# ipe5_target_db register map
Vendor: Texas Instruments
Peripheral module from a debugger description file (folder iva2_arp32).
Address unit: 16 bits
Registers are 32-bit, access per field, reset 0x0 unless marked. A register's access mark holds for its fields unless they carry their own. Offsets are as the file gives them; lines under a group give offsets from that group; [hi:lo] are bit positions; {n}, {i} and the like mark numbered series; 'fields as' and 'values as' point back to an identical list; <NAME> marks a mode.

## DSS (part 1 of 2) — ipxact12_to_ccs_generated
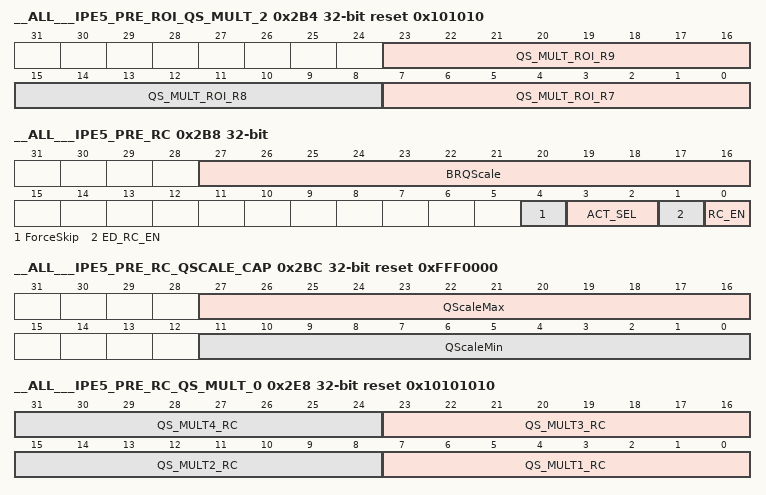
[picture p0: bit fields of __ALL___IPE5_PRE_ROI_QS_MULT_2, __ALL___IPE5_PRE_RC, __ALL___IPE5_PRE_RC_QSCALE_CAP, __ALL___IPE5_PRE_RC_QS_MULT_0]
0x2B4 __ALL___IPE5_PRE_ROI_QS_MULT_2 reset 0x101010 — Multiplication Factors to modify the row level Qscale with. The factors are in Q4.4 format. modifiedQscale = (baseRowQscale * QS_MULT_ROI_Rx) >> 4.
  [23:16] QS_MULT_ROI_R9 rw — 8-bit Qscale multiplication factor.
  [15:8] QS_MULT_ROI_R8 rw — 8-bit Qscale multiplication factor.
  [7:0] QS_MULT_ROI_R7 rw — 8-bit Qscale multiplication factor.
0x2B8 __ALL___IPE5_PRE_RC — IPE5 Rate Control register.
  [27:16] BRQScale rw — Base ROW level Qscale value. Expressed in Q4 format. To be programmed by ICONT at row level.
  [4] ForceSkip rw — ForceSkip information to be updated by ICONT at row level along with BRQScale. This information is passed onto IME and consumed by IPE5.
  [3:2] ACT_SEL rw — Activity select option. 00 : Choose 16X16 activity. 01 : Choose 8X8 activity. 10 : Choose 4X4 activity. 11 : Reserved. If set, by default will use 4X4 activity.
  [1] ED_RC_EN rw — Edge Detection result to be used for Rate control. 0: Text Detection result is not used. 1: Text detection result will modify Qscale for Rate Control.
  [0] RC_EN rw — Enable bit for IPE5 rate control. 0 : Rate control is disabled. 1 : Rate control is enabled.
0x2BC __ALL___IPE5_PRE_RC_QSCALE_CAP reset 0xFFF0000 — Maximum and Minimum values of QScale to be used. The RC modified QScale will be clipped in this range.
  [27:16] QScaleMax rw — MaximumQScale for the current picture.
  [11:0] QScaleMin rw — Minimum QScale for the current picture.
{0x2BC+4i} __ALL___IPE5_PRE_RC_TH{i}_H (i=1..5) — Previous picture activity threshold {i}. 19 bits for 16X16 in case of 8bpp. 17 bits for 8X8 in case of 8bpp. 15 bits for 4X4 in case of 8bpp.
  [18:0] ACT_TH{i}_H rw — Previous frame activity based Threshold.
{0x2BC+4i} __ALL___IPE5_PRE_RC_TH{i}_L (i=6..10) — Previous picture activity threshold {i}. 19 bits for 16X16 in case of 8bpp. 17 bits for 8X8 in case of 8bpp. 15 bits for 4X4 in case of 8bpp.
  [18:0] ACT_TH{i}_L rw — Previous frame activity based Threshold.
0x2E8 __ALL___IPE5_PRE_RC_QS_MULT_0 rw reset 0x10101010 — Multiplication Factors to modify the row level Qscale with. The factors are in Q4.4 format. modifiedQscale = (baseRowQscale * QS_MULTx_RC ) >> 4.
  [8n-1:8n-8] QS_MULT{n}_RC (n=1..4) — 8-bit Qscale multiplication factor.
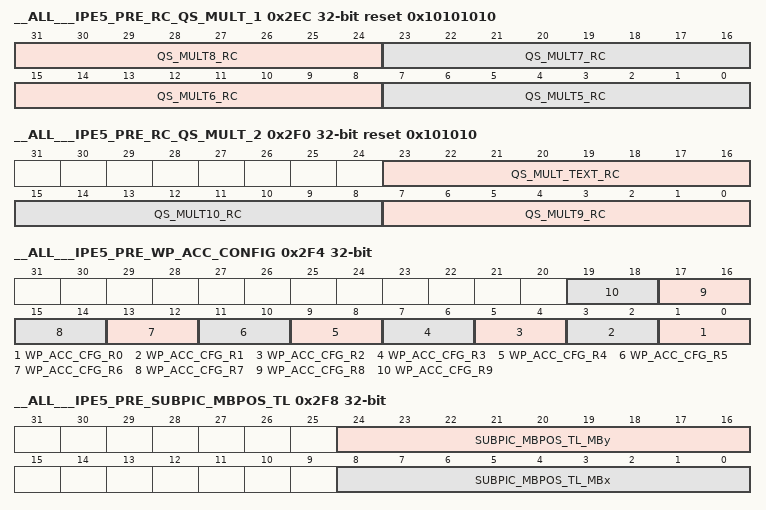
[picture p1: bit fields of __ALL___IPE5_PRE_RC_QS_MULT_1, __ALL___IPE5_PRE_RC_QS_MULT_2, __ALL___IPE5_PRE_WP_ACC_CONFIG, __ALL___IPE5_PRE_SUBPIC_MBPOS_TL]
0x2EC __ALL___IPE5_PRE_RC_QS_MULT_1 rw reset 0x10101010 — Multiplication Factors to modify the row level Qscale with. The factors are in Q4.4 format. modifiedQscale = (baseRowQscale * QS_MULTx_RC ) >> 4.
  [31:24] QS_MULT8_RC — 8-bit Multipliation factor for QScale modulation in text regions.
  [23:16] QS_MULT7_RC — 8-bit Qscale multiplication factor.
  [15:8] QS_MULT6_RC — 8-bit Qscale multiplication factor.
  [7:0] QS_MULT5_RC — 8-bit Qscale multiplication factor.
0x2F0 __ALL___IPE5_PRE_RC_QS_MULT_2 reset 0x101010 — Multiplication Factors to modify the row level Qscale with. The factors are in Q4.4 format. modifiedQscale = (baseRowQscale * QS_MULTx _RC) >> 4.
  [23:16] QS_MULT_TEXT_RC rw — 8-bit Qscale multiplication factor.
  [15:8] QS_MULT10_RC rw — 8-bit Qscale multiplication factor.
  [7:0] QS_MULT9_RC rw — 8-bit Qscale multiplication factor.
0x2F4 __ALL___IPE5_PRE_WP_ACC_CONFIG — Weighted Prediction accumulator feature control register.
  [2n+1:2n] WP_ACC_CFG_R{n} rw (n=0..9) — Region{n} accumulation for sum and sum_sqr for even and odd lines control. 0=> sum/sum_sqr is both odd and even lines. 1=> sum/sum_sqr is for odd lines only. 2,3=> sum/sum_sqr is for even lines only.
0x2F8 __ALL___IPE5_PRE_SUBPIC_MBPOS_TL — Top and Left position of MB for a sub-picture where pre-encode pass will operate on.
  [24:16] SUBPIC_MBPOS_TL_MBy rw — MBy value.
  [8:0] SUBPIC_MBPOS_TL_MBx rw — MBx value.
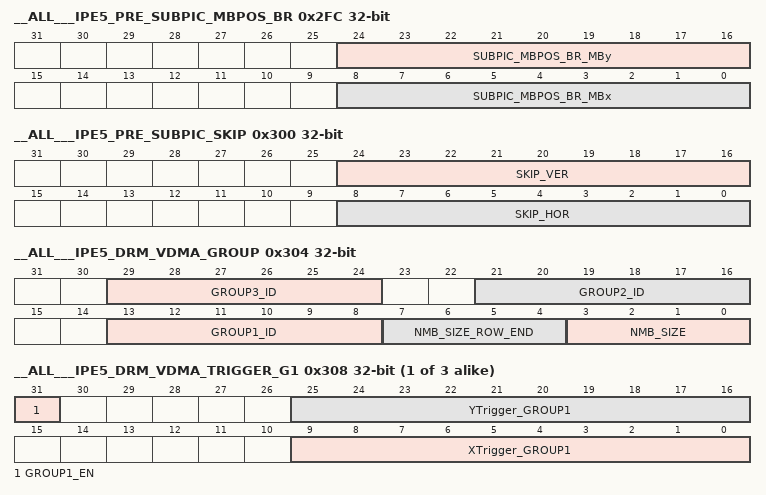
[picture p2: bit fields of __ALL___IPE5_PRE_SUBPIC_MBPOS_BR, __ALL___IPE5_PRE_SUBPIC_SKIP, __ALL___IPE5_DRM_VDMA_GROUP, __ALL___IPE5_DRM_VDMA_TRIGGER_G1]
0x2FC __ALL___IPE5_PRE_SUBPIC_MBPOS_BR — Right and Bottom position of MB for a sub-picture where pre-encode pass will operate on.
  [24:16] SUBPIC_MBPOS_BR_MBy rw — MBy value.
  [8:0] SUBPIC_MBPOS_BR_MBx rw — MBx value.
0x300 __ALL___IPE5_PRE_SUBPIC_SKIP — The register has information on N MB's to pick per VDMA access. Register also has details on horizontal and vertical skip in the sub-picture. Used only for pre-encode pass.
  [24:16] SKIP_VER rw — Vertical skip value in sub-picture. For 8K rows, the maximum value can be expressed in 9-bits.
  [8:0] SKIP_HOR rw — Horizontal skip value in sub-picture. For a 8K row, the maximum value can be expressed in 9-bits.
0x304 __ALL___IPE5_DRM_VDMA_GROUP — VDMA Trigger Interface control MMR.
  [29:24] GROUP3_ID rw — Group3 ID. Only valid in full-encode pass interlaced input and used for last row of frame when MB padding is needed. If MB-padding is not needed this group is not needed.
  [21:16] GROUP2_ID rw — Group2 ID. Only valid in full-encode pass and used for last row of frame when MB padding is needed. If MB-padding is not needed this group is not needed.
  [13:8] GROUP1_ID rw — Group1 ID. This is a 6-bit value. Only group 1 is valid for pre-encode pass.
  [7:4] NMB_SIZE_ROW_END rw — Value of number of MB fetch at the row end. This value is always less and N. The supported values are 0 to 15. 0000 : 0 (Default, indicates M is not used) 0001 : M=1 0010 : M=2 0011 : M=3 0100 : M=4 ... 1111 : M=15
  [3:0] NMB_SIZE rw — Number of MB's to fetch for original pixels for non end of row. N can be end of row fetch also, in case width is a multiple of N. Supported values of N are 1 to 16. 0000 : N = 1 0001 : N = 2 0010 : N = 3 0011 : N = 4 ... 1111 : N = 16
{0x304+4i} __ALL___IPE5_DRM_VDMA_TRIGGER_G{i} (i=1..3) — Group{i} trigger control. IPE5 DRM VDMA MMR to indicate the number of triggers needed for the Group{i} MB's.
  [31] GROUP{i}_EN rw — Enable bit for GROUP{i}. 1=> GROUP{i} enabled. 0=> GROUP{i} disabled.
  [25:16] YTrigger_GROUP{i} rw — Indicates the number of rows (Y triggers) in group{i}.
  [9:0] XTrigger_GROUP{i} rw — Indicates the number of triggers in X direction needed for Group {i}.
0x400 __ALL___PID ro reset 0x4C070300 — IPE5 Peripheral ID Register.
  [31:0] PID — Peripheral ID value. This is still not the final value.
0x404 __ALL___SYSCONFIG — Control Register for IPGenericSYSCONFIG.
  [0] SOFTRESET rw — Software reset Read0: Reset done, no pending action Read1: Reset (software or other) on going Write0: No action Write1: Initiate software reset
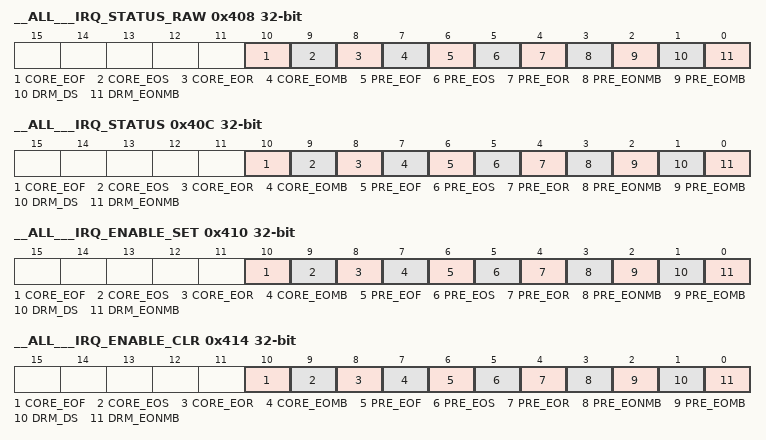
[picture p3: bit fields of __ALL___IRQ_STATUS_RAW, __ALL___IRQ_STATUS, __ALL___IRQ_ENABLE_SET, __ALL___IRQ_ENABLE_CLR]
0x408 __ALL___IRQ_STATUS_RAW — RAW interrupt status for IPE5. Raw status is set even if event is not enabled. Write 1 to set the (raw) status, mostly for debug. The following is the behavior for read/write into each of the individual fields : Write 0: No action Write 1: Set event (for debug) Read 0: No event pending Read 1: Event pending
  [10] CORE_EOF rw — CORE End of Frame Status
  [9] CORE_EOS rw — CORE End of Slice Status
  [8] CORE_EOR rw — CORE End of Row Status
  [7] CORE_EOMB rw — CORE End of MB Status
  [6] PRE_EOF rw — PRE End of Frame Status
  [5] PRE_EOS rw — PRE End of Slice Status
  [4] PRE_EOR rw — PRE End of Row Status
  [3] PRE_EONMB rw — PRE End of N MB status
  [2] PRE_EOMB rw — PRE End of MB Status
  [1] DRM_DS rw — DRM Data Sync Status.
  [0] DRM_EONMB rw — DRM End of N MacroBlock fetch Status.
0x40C __ALL___IRQ_STATUS — Status of enabled sources for interrupt IPE5. The individual status bits are not set, unless the source is enabled (by setting corresponding bit in IRQ_ENABLE_SET register) Write "1" to specific bit in this register to clear the status after interrupt has been serviced. Note : Writing "1" clears the "raw" status as well Note : Writing "1" generates internal EOI. The interrupt line is pulsed again, if any of the interrupt sources are still active (any of the status bits are "1") after the write of "1". The following is the behavior for read/write into each of the individual fields : Write 0: No action Write 1: Clear (raw) event - clears the corresponding bit in this register as well as the "raw" status bit in the IRQ_STATUS_RAW register Read 0: No enabled event pending Read 1: Event pending
  [10] CORE_EOF rw — CORE End of Frame status
  [9] CORE_EOS rw — CORE End of Slice status
  [8] CORE_EOR rw — CORE End of Row status
  [7] CORE_EOMB rw — CORE End of MB status
  [6] PRE_EOF rw — PRE End of Frame status
  [5] PRE_EOS rw — PRE End of Slice status
  [4] PRE_EOR rw — PRE End of Row status
  [3] PRE_EONMB rw — PRE End of N MB status
  [2] PRE_EOMB rw — PRE End of MB status
  [1] DRM_DS rw — DRM Data Sync Interrupt Status.
  [0] DRM_EONMB rw — DRM End of N MacroBlock fetch Status.
0x410 __ALL___IRQ_ENABLE_SET — Interrupt enable for each of the sources for interrupt IPE5. Writing "1" to specific field in this register enables the corresponding source for interrupt generatation The read value reflects whether the corresponding source is enabled/disabled for interrupt generation The following is the behavior for read/write into each of the individual fields : Write 0: No action Write 1: Enable interrupt Read 0: Interrupt disabled (masked) Read 1: Interrupt enabled
  [10] CORE_EOF rw — CORE End of Frame interrupt enable
  [9] CORE_EOS rw — CORE End of Slice interrupt enable
  [8] CORE_EOR rw — CORE End of Row interrupt enable
  [7] CORE_EOMB rw — CORE End of MB interrupt enable
  [6] PRE_EOF rw — PRE End of Frame interrupt enable
  [5] PRE_EOS rw — PRE End of Slice interrupt enable
  [4] PRE_EOR rw — PRE End of Row interrupt enable
  [3] PRE_EONMB rw — PRE End of N MB Interrupt Enable
  [2] PRE_EOMB rw — PRE End of MB interrupt enable
  [1] DRM_DS rw — DRM Data Sync Interrupt enable.
  [0] DRM_EONMB rw — DRM End of N MacroBlock Interrupt Enable.
0x414 __ALL___IRQ_ENABLE_CLR — Interrupt disable for each of the sources for interrupt IPE5. Writing "1" to specific field in this register disables the corresponding source for interrupt generatation The read value reflects whether the corresponding source is enabled/disabled for interrupt generation The following is the behavior for read/write into each of the individual fields : Write 0: No action Write 1: Disable interrupt Read 0: Interrupt disabled (masked) Read 1: Interrupt enabled
  [10] CORE_EOF rw — PRE End of Frame interrupt disable
  [9] CORE_EOS rw — PRE End of Slice interrupt disable
  [8] CORE_EOR rw — PRE End of Row interrupt disable
  [7] CORE_EOMB rw — CORE End of MB interrupt disable
  [6] PRE_EOF rw — PRE End of Frame interrupt disable
  [5] PRE_EOS rw — PRE End of Slice interrupt disable
  [4] PRE_EOR rw — PRE End of Row interrupt disable
  [3] PRE_EONMB rw — PRE End of N MB Interrupt Disable.
  [2] PRE_EOMB rw — PRE End of MB interrupt disable
  [1] DRM_DS rw — DRM Data Sync Interrupt disable.
  [0] DRM_EONMB rw — DRM End of N MacroBlock Interrupt disable.
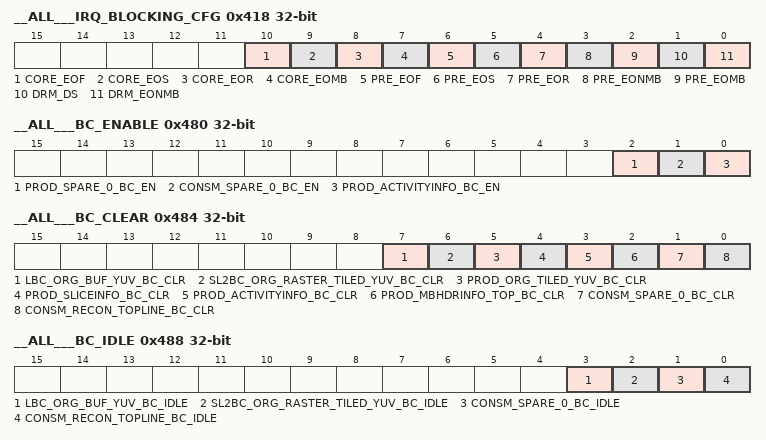
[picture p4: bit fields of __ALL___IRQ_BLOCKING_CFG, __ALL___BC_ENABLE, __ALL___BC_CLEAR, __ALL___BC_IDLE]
0x418 __ALL___IRQ_BLOCKING_CFG — Interrupt blocking configuration for interrupt IPE5. If a bit in this register is set to "1", the IPE5-DRM thread halts after it generates an interrupt for the corresponding interrupt source, and waits for interrupt acknowledgement for that interrupt line before continuing execution. If a bit in this register is set to "0", the IPE5-DRM does not halt after it generates an interrupt for the corresponding interrupt source The configuration in this register only apply to enabled interrupt sources.
  [10] CORE_EOF rw — CORE End of Frame Interrupt blocking configuration.
  [9] CORE_EOS rw — CORE End of Slice Interrupt blocking configuration.
  [8] CORE_EOR rw — CORE End of Row Interrupt blocking configuration.
  [7] CORE_EOMB rw — CORE End of MB Interrupt blocking configuration.
  [6] PRE_EOF rw — PRE End of Frame Interrupt blocking configuration.
  [5] PRE_EOS rw — PRE End of Slice Interrupt blocking configuration.
  [4] PRE_EOR rw — PRE End of Row Interrupt blocking configuration.
  [3] PRE_EONMB rw — PRE End of N MB Interrupt blocking Configuration
  [2] PRE_EOMB rw — PRE End of MB Interrupt blocking configuration.
  [1] DRM_DS rw — DRM Data Sync Interrupt blocking configuration.
  [0] DRM_EONMB rw — DRM End of N MacroBlock Interrupt blocking configuration.
0x480 __ALL___BC_ENABLE — BC_ENABLE Bits for specific BC's instantiated in IPE5. If this register is 0, the corresponding BC's ready is not looked for thread to proceed its execution.
  [2] PROD_SPARE_0_BC_EN rw — BC_ENABLE bit for PROD_SPARE_0 SL2BC. If set to '0', then BC availability is not checked for MB execution.
  [1] CONSM_SPARE_0_BC_EN rw — BC_ENABLE bit for CONSM_SPARE_0 SL2BC. If set to '0', then BC availability is not checked for MB execution.
  [0] PROD_ACTIVITYINFO_BC_EN rw — BC_ENABLE bit for ACTIVITYNIFO SL2BC. If set to '0', then activity info BC availability is not checked for MB execution and activity-info is not written into SL2.
0x484 __ALL___BC_CLEAR — BC_CLEAR Bits for all the BC's instantiated in IPE5. The bits set to '1' are auto-cleared in 1 cycle. So, the read will always yield '0'.
  [7] LBC_ORG_BUF_YUV_BC_CLR rw — BC_CLEAR bit for LBC_ORG_BUF LBC.
  [6] SL2BC_ORG_RASTER_TILED_YUV_BC_CLR rw — BC_CLEAR bit for SL2BC_ORG_RASTER_TILED_YUV SL2BC.
  [5] PROD_ORG_TILED_YUV_BC_CLR rw — BC_CLEAR bit for PROD_ORG_TILED_YUV SL2BC.
  [4] PROD_SLICEINFO_BC_CLR rw — BC_CLEAR bit for PROD_SLICEINFO SL2BC.
  [3] PROD_ACTIVITYINFO_BC_CLR rw — BC_CLEAR bit for PROD_ACTIVITYNIFO SL2BC.
  [2] PROD_MBHDRINFO_TOP_BC_CLR rw — BC_CLEAR bit for PROD_MBHDRINFO_TOP SL2BC.
  [1] CONSM_SPARE_0_BC_CLR rw — BC_CLEAR bit for CONSM_SPARE_0 SL2BC.
  [0] CONSM_RECON_TOPLINE_BC_CLR rw — BC_CLEAR bit for CONSM_RECON_TOPLINE SL2BC.
0x488 __ALL___BC_IDLE — BC_IDLE Bits for all the BC's instantiated in IPE5. The bits set to '1' are auto-cleared in 1 cycle. So, the read will always yield '0'.
  [3] LBC_ORG_BUF_YUV_BC_IDLE rw — BC_IDLE bit for LBC_ORG_BUF LBC.
  [2] SL2BC_ORG_RASTER_TILED_YUV_BC_IDLE rw — BC_IDLE bit for SL2BC_ORG_RASTER_TILED_YUV SL2BC.
  [1] CONSM_SPARE_0_BC_IDLE rw — BC_IDLE bit for CONSM_SPARE_0 SL2BC.
  [0] CONSM_RECON_TOPLINE_BC_IDLE rw — BC_IDLE bit for CONSM_RECON_TOPLINE SL2BC.
0x48C __ALL___START_OF_FRAME — Indicates that the start of a new frame to the IPE5. Self clearing bit. This will be used for all use cases. Write[0] : No impact Write[1] : Indicates start of frame for IPE5. Read[0] : Operation is not on SOF Read[1] : Operation is on SOF.
  [0] START_OF_FRAME rw — 1=> Indicates start of frame to IPE5. This has to be set by ICONT. 0=> Indicates that current operation is not on start of frame.
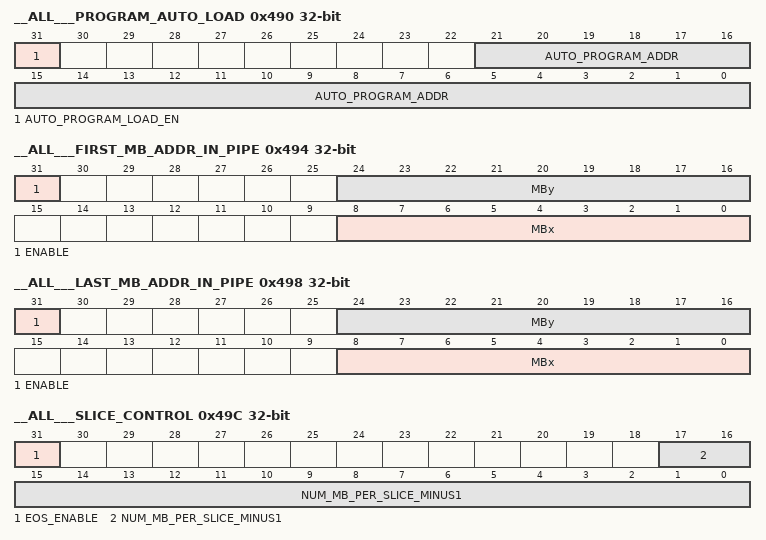
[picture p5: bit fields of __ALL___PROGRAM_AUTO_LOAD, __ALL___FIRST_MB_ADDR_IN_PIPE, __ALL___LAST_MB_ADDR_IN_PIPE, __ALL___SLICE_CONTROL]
0x490 __ALL___PROGRAM_AUTO_LOAD — SL2 base address for fetching MMR programmation data for BUFFER_BA_MMR, BUFFER_CONTROL_MMR and FUNC_MMR. IPE5 will fetch 1024 bytes (64 SL2 access) to update these MMR regions.
  [31] AUTO_PROGRAM_LOAD_EN rw — 1 => Program auto load enabled. 0 => No autoload is required. MMR programmed by ICONT.
  [21:0] AUTO_PROGRAM_ADDR rw — SL2 Address for reference pixels.
0x494 __ALL___FIRST_MB_ADDR_IN_PIPE — Indicates the MB location from where IPE5 must start. This is needed for channel switching use case and H.241 rewind use case.
  [31] ENABLE rw — Self clearing bit after init. 1=> Use (MBx, MBy) in this register to start in case of rewind and continue OR channel switch use case. 0=> MBx, MBy is ignored. Normal encode flow.
  [24:16] MBy rw — MB y location.
  [8:0] MBx rw — MB x location.
0x498 __ALL___LAST_MB_ADDR_IN_PIPE — Indicates the MB location where IPE5 must pipedown. This is needed for channel switching use case.
  [31] ENABLE rw — 1=> Use (MBx, MBy) in this register to insert end of pipe and end of slice for current channel. 0=> MBx, MBy is ignored. Normal encode flow.
  [24:16] MBy rw — MB y location.
  [8:0] MBx rw — MB x location.
0x49C __ALL___SLICE_CONTROL — Slice size control register. Indicates number of MB's per slice.
  [31] EOS_ENABLE rw — End of slice enable. For H.241 use case, this bit has to be set to '0'. EOS is not inserted by IPE in this case.
  [17:0] NUM_MB_PER_SLICE_MINUS1 rw — Number of MB's per slice. Once IPE5 has processed these many number of MB's, the end_of_slice flag in MB-info will be asserted. This value is valid only when EOS_ENABLE is set to '1'.
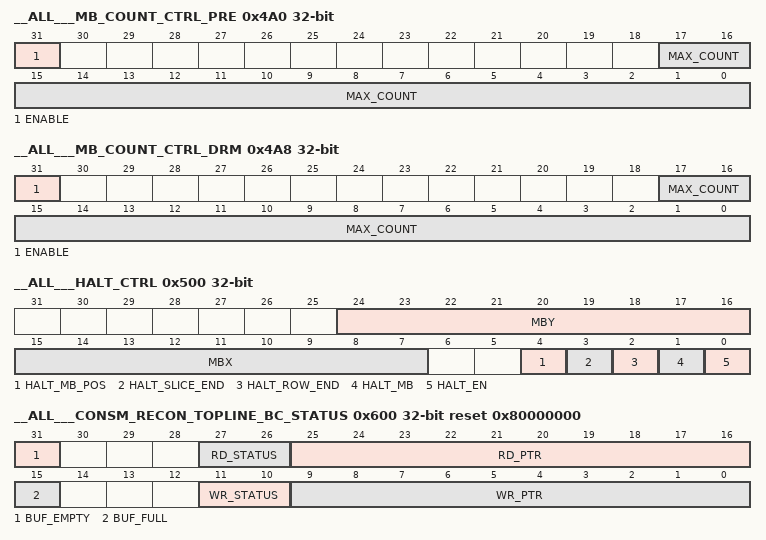
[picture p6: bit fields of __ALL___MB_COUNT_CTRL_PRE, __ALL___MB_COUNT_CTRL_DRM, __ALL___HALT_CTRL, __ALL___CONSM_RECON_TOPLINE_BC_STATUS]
0x4A0 __ALL___MB_COUNT_CTRL_PRE — N MB interrupt control register for IPE5-PRE.
  [31] ENABLE rw — To enable or disable the counter to generate interrupt after N MB.
  [17:0] MAX_COUNT rw — Number of MBs, after which interrupt needs to be generated. ( if 1, interrupt generated every MB ); MAX_COUNT of 0 is illegal; EN bit should be 0 if MAX_COUNT = 0.
0x4A4 __ALL___MB_COUNTER_PRE — N MB interrupt count register for IPE5-PRE.
  [17:0] MB_COUNTER rw — If MB_COUNT_CTRL_PRE.ENABLE == 1, incremented first, and then compared against MB_COUNT_CTRL_PRE.MAX_COUNT for each MB executed. If compare matches ( && MB_COUNT_CTRL_PRE.ENABLE == 1 ), interrupt is signaled to HTS; HTS generates interrupt provided interrupt source enabled after Tend. MB_COUNTER_PRE is reset to 0.
0x4A8 __ALL___MB_COUNT_CTRL_DRM — K*N MB interrupt control register for IPE5-DRM. This register provides the DATASYNC Support.
  [31] ENABLE rw — To enable or disable the counter to generate interrupt after K*N MB.
  [17:0] MAX_COUNT rw — Number of K (MAX_COUNT), N MBs, after which interrupt needs to be generated. ( if 1, interrupt generated every N MB ); MAX_COUNT of 0 is illegal; EN bit should be 0 if MAX_COUNT = 0.
0x4AC __ALL___MB_COUNTER_DRM — K*N MB interrupt count register for IPE5-DRM.
  [17:0] MB_COUNTER rw — If MB_COUNT_CTRL_DRM.ENABLE == 1, incremented first, and then compared against MB_COUNT_CTRL_DRM.MAX_COUNT for each N MB executed/fetched. If compare matches ( && MB_COUNT_CTRL_DRM.ENABLE == 1 ), interrupt is signaled to HTS; HTS generates interrupt provided interrupt source enabled after Tend. MB_COUNTER_DRM is reset to 0.
0x500 __ALL___HALT_CTRL — Processing HALT control register.
  [24:16] MBY rw — Y co-ordinate of MB position at which IPE5 processing should halt.
  [15:7] MBX rw — X co-ordinate of MB position at which IPE5 processing should halt.
  [4] HALT_MB_POS rw — Halt after processing MB defined by MBX and MBY position. 0: Disabled. 1: Enabled.
  [3] HALT_SLICE_END rw — Halt after processing every SLICE. 0: Disabled. 1: Enabled.
  [2] HALT_ROW_END rw — Halt after processing every ROW. 0: Disabled. 1: Enabled.
  [1] HALT_MB rw — Halt after processing every MB. 0: Disabled. 1: Enabled.
  [0] HALT_EN rw — HALT enable bit. 0: IPE5 is normal processing. No half support. 1: IPE5 is in debug mode. Halt can be at end of MB, end of ROW, end of slice OR given MB position.
0x600 __ALL___CONSM_RECON_TOPLINE_BC_STATUS ro reset 0x80000000 — Read_only status register.
  [31] BUF_EMPTY — buffer empty status ‘1’ -> buffer is empty ‘0’ -> buffer is not empty
  [27:26] RD_STATUS — Indicates the BC status on the read side “00” rd_core_busy=0 & rd_bc_ready=0 “01” rd_core_busy=0 & rd_bc_ready=1 “1x” rd_core_busy=1
  [25:16] RD_PTR — Read pointer.
  [15] BUF_FULL — buffer full status ‘1’ -> buffer is full ‘0’ -> buffer is not full
  [11:10] WR_STATUS — Indicates the BC status on the write side “00” wr_core_busy=0 & wr_bc_ready=0 “01” wr_core_busy=0 & wr_bc_ready=1 “1x” wr_core_busy=1
  [9:0] WR_PTR — Write pointer.
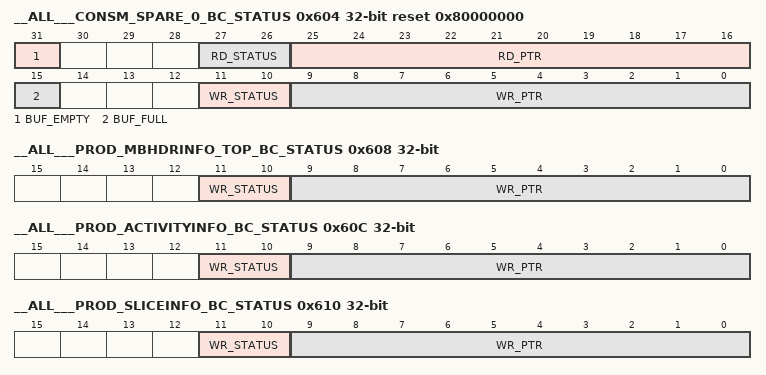
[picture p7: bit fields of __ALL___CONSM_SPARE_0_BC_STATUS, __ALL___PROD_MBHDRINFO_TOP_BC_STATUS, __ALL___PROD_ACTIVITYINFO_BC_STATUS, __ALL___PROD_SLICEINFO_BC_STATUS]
0x604 __ALL___CONSM_SPARE_0_BC_STATUS ro reset 0x80000000 — Read_only status register.
  fields as __ALL___CONSM_RECON_TOPLINE_BC_STATUS
0x608 __ALL___PROD_MBHDRINFO_TOP_BC_STATUS ro — Read_only status register.
  [11:10] WR_STATUS — Indicates the BC status on the write side “00” wr_core_busy=0 & wr_bc_ready=0 “01” wr_core_busy=0 & wr_bc_ready=1 “1x” wr_core_busy=1
  [9:0] WR_PTR — Write pointer.
0x60C __ALL___PROD_ACTIVITYINFO_BC_STATUS ro — Read_only status register.
  fields as __ALL___PROD_MBHDRINFO_TOP_BC_STATUS
0x610 __ALL___PROD_SLICEINFO_BC_STATUS ro — Read_only status register.
  fields as __ALL___PROD_MBHDRINFO_TOP_BC_STATUS
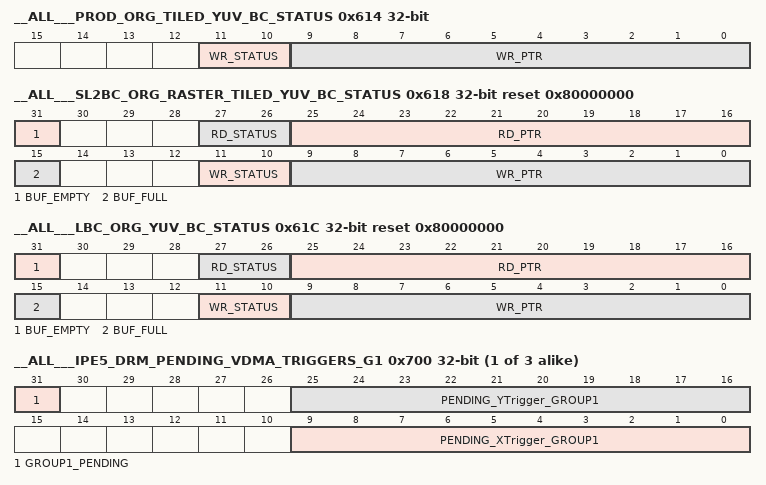
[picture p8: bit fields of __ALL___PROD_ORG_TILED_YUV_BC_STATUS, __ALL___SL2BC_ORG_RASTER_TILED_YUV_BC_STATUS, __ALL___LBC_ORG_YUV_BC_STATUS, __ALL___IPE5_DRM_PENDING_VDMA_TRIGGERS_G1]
0x614 __ALL___PROD_ORG_TILED_YUV_BC_STATUS ro — Read_only status register.
  fields as __ALL___PROD_MBHDRINFO_TOP_BC_STATUS
0x618 __ALL___SL2BC_ORG_RASTER_TILED_YUV_BC_STATUS ro reset 0x80000000 — Read_only status register.
  fields as __ALL___CONSM_RECON_TOPLINE_BC_STATUS
0x61C __ALL___LBC_ORG_YUV_BC_STATUS ro reset 0x80000000 — Read_only status register.
  fields as __ALL___CONSM_RECON_TOPLINE_BC_STATUS
{0x6FC+4i} __ALL___IPE5_DRM_PENDING_VDMA_TRIGGERS_G{i} (i=1..3) — Indicates the pending vdma triggers in VDMA group{i} for IPE5-DRM.
  [31] GROUP{i}_PENDING rw — 0 => Group{i} triggers are completed. 1 => Group{i} triggers are pending.
  [25:16] PENDING_YTrigger_GROUP{i} rw — Indicates the number of pending row(Y) triggers for group{i}.
  [9:0] PENDING_XTrigger_GROUP{i} rw — Indicates the number of pending X triggers for the current row in Group {i}.
0x70C __ALL___IPE5_DRM_PENDING_WRPTR_INC_ORG_RASTER_TILED — Indicates the pending write pointer increments for ORG_BUF .
  [3:0] PENDING_INC rw — Indicates the number of pending write pointer increments for ORG_BUF_RASTER_TILED SL2BC.
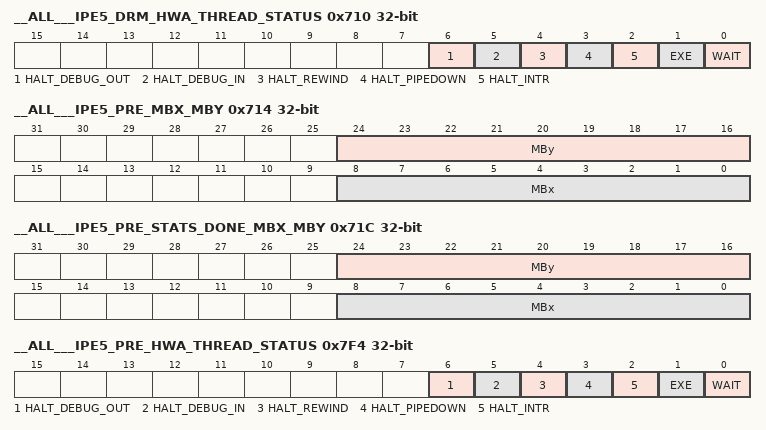
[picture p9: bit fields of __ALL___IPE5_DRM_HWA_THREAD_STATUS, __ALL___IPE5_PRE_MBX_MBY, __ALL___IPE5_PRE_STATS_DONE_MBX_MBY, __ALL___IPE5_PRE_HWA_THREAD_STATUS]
0x710 __ALL___IPE5_DRM_HWA_THREAD_STATUS ro — IPE5-DRM thread status.
  [6] HALT_DEBUG_OUT — Halted because of debug out request
  [5] HALT_DEBUG_IN — Halted because of pi_emu
  [4] HALT_REWIND — Halted because of rewind
  [3] HALT_PIPEDOWN — Thread piped down
  [2] HALT_INTR — Halted beacuse of interrupt request
  [1] EXE — Execution state
  [0] WAIT — Wait for Tstart request
0x714 __ALL___IPE5_PRE_MBX_MBY ro — MBx and MBy location of current MB being processed in IPE5_PRE.
  [24:16] MBy — MBy Location.
  [8:0] MBx — MBx location.
0x718 __ALL___IPE5_PRE_CUR_MB_IN_SLICE ro — Indicates the current MB count being processed in IPE5_PRE.
  [17:0] CURMBINSLICE — Current MB's complete count in slice.
0x71C __ALL___IPE5_PRE_STATS_DONE_MBX_MBY — MBx and MBy location of MB in IPE5_PRE, till which point the statistics computtion is complete. This is useful for H.241 use case.
  [24:16] MBy rw — MBy Location.
  [8:0] MBx rw — MBx location.
0x720 __ALL___IPE5_PRE_SUM_ACT4X4_H ro — Higher 32-bits of 4X4 block activity over a frame. For 8BPP mode, this register is not needed. Only required for 10BPP and higher.
0x724 __ALL___IPE5_PRE_SUM_ACT4X4_L — Lower 32-bits of 4X4 block activity over a frame.
  [30:0] SUM_ACT4X4 rw — Lower 31-bits of Accumulated values of ACT_4X4.
0x728 __ALL___IPE5_PRE_SUM_ACT8X8_H — Higher 1-bits of 8X8 block activity over a frame.
  [0] SUM_ACT8X8 rw — Higher 1-bit of Accumulated values of ACT_8X8.
0x72C __ALL___IPE5_PRE_SUM_ACT8X8_L rw — Lower 32-bits of 8X8 block activity over a frame.
  [31:0] SUM_ACT8X8 — Lower 32-bits of Accumulated values of ACT_8X8.
0x730 __ALL___IPE5_PRE_SUM_ACT16X16_H — Higher 3-bits of 16X16 block activity over a frame.
  [2:0] SUM_ACT16X16 rw — Higher 3-bits of Accumulated values of ACT_16X16.
0x734 __ALL___IPE5_PRE_SUM_ACT16X16_L rw — Lower 32-bits of 16X16 block activity over a frame.
  [31:0] SUM_ACT16X16 — Lower 32-bits of Accumulated values of ACT_16X16.
0x738 __ALL___IPE5_PRE_ED_TEXT_MB_COUNT — Counter for Text MB's in picture.
  [18:0] CNT rw — Count value.
0x73C __ALL___IPE5_PRE_ED_TEXTURE_MB_COUNT — Counter for Texture MB's in picture.
  [18:0] CNT rw — Count value.
0x740 __ALL___IPE5_PRE_ED_FLAT_MB_COUNT — Counter for Flat MB's in picture.
  [18:0] CNT rw — Count value.
{0x744+8i} __ALL___IPE5_PRE_WP_R{i}_SUM_H (i=0..9) — Sum of pixels in Region {i}. The sum can be of 34-bits max for 8bpp. This MMR stores the higher 2 bits.
  [1:0] SUM_R{i}_H rw — Higher bits of SUM in case of 8bpp.
{0x748+8i} __ALL___IPE5_PRE_WP_R{i}_SUM_L rw (i=0..9) — Sum of pixels in Region {i}. The sum can be of 34-bits max for 8bpp. This MMR stores the lower 32 bits.
  [31:0] SUM_R{i}_L — Lower 32 bits of SUM in case of 8bpp.
{0x794+8i} __ALL___IPE5_PRE_WP_R{i}_SUM_SQR_H (i=0..9) — Sum of squares of pixels in Region {i}. The sum of squares can be of 42-bits max for 8bpp. This MMR stores the higher 10 bits.
  [9:0] SUM_SQR_R{i}_H rw — Higher 10 bits of SUM of squares in case of 8bpp.
{0x798+8i} __ALL___IPE5_PRE_WP_R{i}_SUM_SQR_L rw (i=0..9) — Sum of squares of pixels in Region {i}. The sum of squares can be of 42-bits max for 8bpp. This MMR stores the lower 32 bits.
  [31:0] SUM_SQR_R{i}_L — Lower 32 bits of SUM of squares in case of 8bpp.
0x7E4 __ALL___IPE5_PRE_PICAFF_FRAME_ACC_H — VD_FRAME_ACC value can be of 34-bits max for 8bpp. This MMR stores the higher 2 bits.
  [1:0] VD_FRAME_ACC rw — Higher 2 bits in case of 8bpp.
0x7E8 __ALL___IPE5_PRE_PICAFF_FRAME_ACC_L rw — VD_FRAME_ACC value can be of 34-bits max for 8bpp. This MMR stores the lower 32 bits.
  [31:0] VD_FRAME_ACC — Lower 32 bits in case of 8bpp.
0x7EC __ALL___IPE5_PRE_PICAFF_FIELD_ACC_H — VD_FIELD_ACC value can be of 34-bits max for 8bpp. This MMR stores the higher 2 bits.
  [1:0] VD_FIELD_ACC rw — Higher 2 bits in case of 8bpp.
0x7F0 __ALL___IPE5_PRE_PICAFF_FIELD_ACC_L rw — VD_FIELD_ACC value can be of 34-bits max for 8bpp. This MMR stores the lower 32 bits.
  [31:0] VD_FIELD_ACC — Lower 32 bits in case of 8bpp.
0x7F4 __ALL___IPE5_PRE_HWA_THREAD_STATUS ro — IPE5-PRE thread status.
  fields as __ALL___IPE5_DRM_HWA_THREAD_STATUS
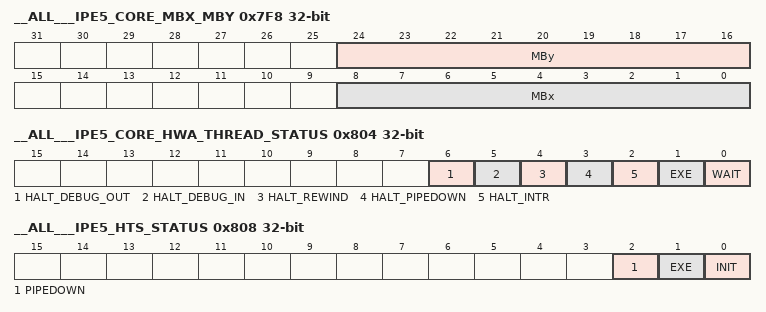
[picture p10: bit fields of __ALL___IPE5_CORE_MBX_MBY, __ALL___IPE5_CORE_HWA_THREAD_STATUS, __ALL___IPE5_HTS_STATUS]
0x7F8 __ALL___IPE5_CORE_MBX_MBY ro — MBx and MBy location of current MB being processed in IPE5_CORE.
  [24:16] MBy — MBy Location.
  [8:0] MBx — MBx location.
0x7FC __ALL___IPE5_CORE_BESTCOST_LUMA ro — SAD value of Best Luma partition type.
  [17:0] BEST_COST
0x800 __ALL___IPE5_CORE_BESTCOST_CHROMA ro — SAD value of Best Chroma partition type.
  [15:0] BEST_COST — SAD value of Best chroma mode.
0x804 __ALL___IPE5_CORE_HWA_THREAD_STATUS ro — IPE5-CORE thread status.
  fields as __ALL___IPE5_DRM_HWA_THREAD_STATUS
0x808 __ALL___IPE5_HTS_STATUS ro — IPE5-HTS status.
  [2] PIPEDOWN — HWA is in pipedown
  [1] EXE — HWA is executing
  [0] INIT — HWA is autoloading/initializing
0x1000 __ALL___WORD rw — Each word of 32-bit is accessible through 32-bit OCP Port.
0x2000 __ALL___WORD rw
0x3000 __ALL___WORD rw
